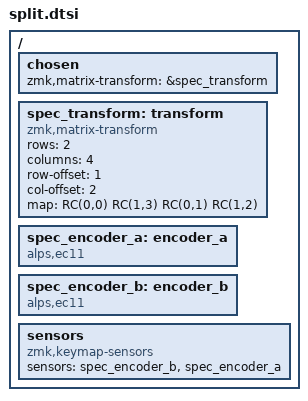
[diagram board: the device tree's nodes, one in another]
/* Synthetic right-part resolved snapshot. Both parts share this full map.
 * cases.json declares left (0,0) and right (1,2) event offsets and scan extents.
 * Offset applies to local events, not to the already-global map below. */
/ {
    chosen { zmk,matrix-transform = &spec_transform; };
    spec_transform: transform {
        compatible = "zmk,matrix-transform";
        rows = <2>;
        columns = <4>;
        row-offset = <1>;
        col-offset = <2>;
        map = <RC(0,0) RC(1,3) RC(0,1) RC(1,2)>;
    };
    spec_encoder_a: encoder_a { compatible = "alps,ec11"; };
    spec_encoder_b: encoder_b { compatible = "alps,ec11"; };
    sensors {
        compatible = "zmk,keymap-sensors";
        sensors = <&spec_encoder_b &spec_encoder_a>;
    };
};
